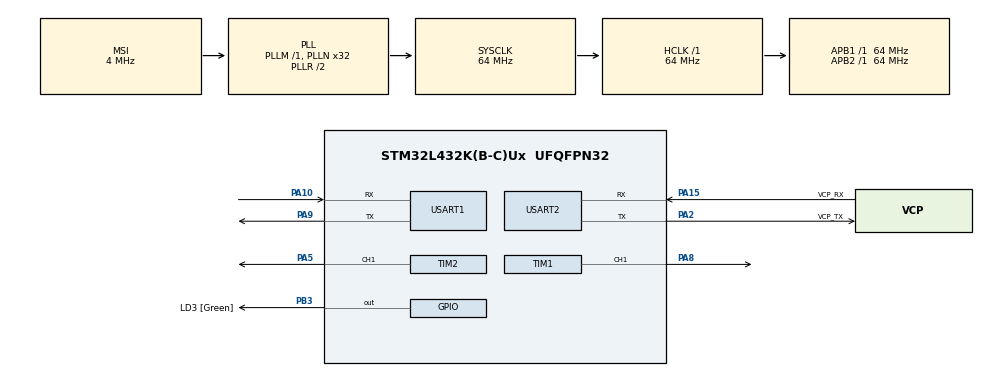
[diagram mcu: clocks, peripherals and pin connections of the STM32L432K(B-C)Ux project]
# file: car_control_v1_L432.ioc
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Mcu.Family=STM32L4
Mcu.Name=STM32L432K(B-C)Ux
Mcu.Package=UFQFPN32
NVIC.PriorityGroup=NVIC_PRIORITYGROUP_4
NVIC.USART1_IRQn=true\:0\:0\:false\:true\:true\:1\:true
NVIC.USART2_IRQn=true\:0\:0\:false\:true\:true\:2\:true
PA0.GPIO_Label=MCO [High speed clock in]
PA0.Mode=HSE-External-Clock-Source-for-LittleOrca
PA0.Signal=RCC_CK_IN
PA10.Mode=Asynchronous
PA10.Signal=USART1_RX
PA13\ (JTMS-SWDIO).GPIO_Label=SWDIO
PA13\ (JTMS-SWDIO).Mode=Serial_Wire
PA13\ (JTMS-SWDIO).Signal=SYS_JTMS-SWDIO
PA14\ (JTCK-SWCLK).GPIO_Label=SWCLK
PA14\ (JTCK-SWCLK).Mode=Serial_Wire
PA14\ (JTCK-SWCLK).Signal=SYS_JTCK-SWCLK
PA15\ (JTDI).GPIO_Label=VCP_RX
PA15\ (JTDI).Mode=Asynchronous
PA15\ (JTDI).Signal=USART2_RX
PA2.GPIO_Label=VCP_TX
PA2.Mode=Asynchronous
PA2.Signal=USART2_TX
PA5.Signal=S_TIM2_CH1
PA8.Signal=S_TIM1_CH1
PA9.Mode=Asynchronous
PA9.Signal=USART1_TX
PB3\ (JTDO-TRACESWO).GPIO_Label=LD3 [Green]
PB3\ (JTDO-TRACESWO).Signal=GPIO_Output
PC14-OSC32_IN\ (PC14).Mode=LSE-External-Oscillator
PC14-OSC32_IN\ (PC14).Signal=RCC_OSC32_IN
PC15-OSC32_OUT\ (PC15).Mode=LSE-External-Oscillator
PC15-OSC32_OUT\ (PC15).Signal=RCC_OSC32_OUT
ProjectManager.HeapSize=0x200
ProjectManager.StackSize=0x400
ProjectManager.TargetToolchain=TrueSTUDIO
RCC.ADCFreq_Value=16000000
RCC.AHBFreq_Value=64000000
RCC.APB1Freq_Value=64000000
RCC.APB1TimFreq_Value=64000000
RCC.APB2Freq_Value=64000000
RCC.APB2TimFreq_Value=64000000
RCC.CortexFreq_Value=64000000
RCC.HCLKFreq_Value=64000000
RCC.HSE_VALUE=8000000
RCC.HSI16_VALUE=16000000
RCC.HSI48_VALUE=48000000
RCC.HSI_VALUE=16000000
RCC.MSI_VALUE=4000000
RCC.PLLMUL=RCC_PLLMUL_4
RCC.PLLN=32
RCC.SYSCLKFreq_VALUE=64000000
RCC.SYSCLKSource=RCC_SYSCLKSOURCE_PLLCLK
RCC.USBFreq_Value=16000000
RCC.VCOOutputFreq_Value=128000000
SH.S_TIM1_CH1.0=TIM1_CH1,PWM Generation1 CH1
SH.S_TIM2_CH1.0=TIM2_CH1,PWM Generation1 CH1
TIM1.Channel-PWM\ Generation1\ CH1=TIM_CHANNEL_1
TIM1.Period=10000-1
TIM1.Prescaler=128-1
TIM1.Pulse-PWM\ Generation1\ CH1=760
TIM2.Channel-PWM\ Generation1\ CH1=TIM_CHANNEL_1
TIM2.Period=10000-1
TIM2.Prescaler=128-1
TIM2.Pulse-PWM\ Generation1\ CH1=760
USART1.VirtualMode-Asynchronous=VM_ASYNC
USART2.VirtualMode-Asynchronous=VM_ASYNC
board=NUCLEO-L432KC

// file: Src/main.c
/* USER CODE BEGIN Header */
/**
  ******************************************************************************
  * @file           : main.c
  * @brief          : Main program body
  ******************************************************************************
  ** This notice applies to any and all portions of this file
  * that are not between comment pairs USER CODE BEGIN and
  * USER CODE END. Other portions of this file, whether
  * inserted by the user or by software development tools
  * are owned by their respective copyright owners.
  *
  * COPYRIGHT(c) 2019 STMicroelectronics
  *
  * Redistribution and use in source and binary forms, with or without modification,
  * are permitted provided that the following conditions are met:
  *   1. Redistributions of source code must retain the above copyright notice,
  *      this list of conditions and the following disclaimer.
  *   2. Redistributions in binary form must reproduce the above copyright notice,
  *      this list of conditions and the following disclaimer in the documentation
  *      and/or other materials provided with the distribution.
  *   3. Neither the name of STMicroelectronics nor the names of its contributors
  *      may be used to endorse or promote products derived from this software
  *      without specific prior written permission.
  *
  * THIS SOFTWARE IS PROVIDED BY THE COPYRIGHT HOLDERS AND CONTRIBUTORS "AS IS"
  * AND ANY EXPRESS OR IMPLIED WARRANTIES, INCLUDING, BUT NOT LIMITED TO, THE
  * IMPLIED WARRANTIES OF MERCHANTABILITY AND FITNESS FOR A PARTICULAR PURPOSE ARE
  * DISCLAIMED. IN NO EVENT SHALL THE COPYRIGHT HOLDER OR CONTRIBUTORS BE LIABLE
  * FOR ANY DIRECT, INDIRECT, INCIDENTAL, SPECIAL, EXEMPLARY, OR CONSEQUENTIAL
  * DAMAGES (INCLUDING, BUT NOT LIMITED TO, PROCUREMENT OF SUBSTITUTE GOODS OR
  * SERVICES; LOSS OF USE, DATA, OR PROFITS; OR BUSINESS INTERRUPTION) HOWEVER
  * CAUSED AND ON ANY THEORY OF LIABILITY, WHETHER IN CONTRACT, STRICT LIABILITY,
  * OR TORT (INCLUDING NEGLIGENCE OR OTHERWISE) ARISING IN ANY WAY OUT OF THE USE
  * OF THIS SOFTWARE, EVEN IF ADVISED OF THE POSSIBILITY OF SUCH DAMAGE.
  *
  ******************************************************************************
  */
/* USER CODE END Header */

#include "main.h"

TIM_HandleTypeDef htim1;
TIM_HandleTypeDef htim2;

UART_HandleTypeDef huart1;
UART_HandleTypeDef huart2;

uint8_t rxBuffer[5]={0,};

uint8_t rcvFlag = 0;

uint8_t err_neg[40]="err!!Please Enter Positive Number\n\r";
uint8_t err_steer[40]="err!!Please Enter 0~31 Steer\n\r";
uint8_t err_speed[40]="err!!Please Enter 0~4 Speed\n\r";

int input;
int input_steer;
int input_speed;

int input_pwm1;
int input_pwm2;

void SystemClock_Config(void);
static void MX_GPIO_Init(void);
static void MX_USART2_UART_Init(void);
static void MX_USART1_UART_Init(void);
static void MX_TIM1_Init(void);
static void MX_TIM2_Init(void);
static void MX_NVIC_Init(void);
/* USER CODE BEGIN PFP */

static int ascii2int(uint8_t *value);

/* USER CODE END PFP */

int main(void)
{

  /* MCU Configuration--------------------------------------------------------*/

  /* Reset of all peripherals, Initializes the Flash interface and the Systick. */
  HAL_Init();

  /* Configure the system clock */
  SystemClock_Config();

  /* Initialize all configured peripherals */
  MX_GPIO_Init();
  MX_USART2_UART_Init();
  MX_USART1_UART_Init();
  MX_TIM1_Init();
  MX_TIM2_Init();

  /* Initialize interrupts */
  MX_NVIC_Init();
  /* USER CODE BEGIN 2 */
  HAL_TIM_PWM_Start(&htim1, TIM_CHANNEL_1);
  HAL_TIM_PWM_Start(&htim2, TIM_CHANNEL_1);
  /* USER CODE END 2 */

  /* Infinite loop */
  while (1)
  {
	  if(rcvFlag)
	  {
		  input = ascii2int(rxBuffer);
		  input_steer = input >> 3;
		  input_speed = input & 0x7;

		  if(input<0)
		  {
			  HAL_UART_Transmit(&huart2, err_neg, sizeof(err_neg), 10);
		  }
		  else if(input_steer>31)
		  {
			  HAL_UART_Transmit(&huart2, err_steer, sizeof(err_steer), 10);
		  }
		  else if(input_speed>4)
		  {
			  HAL_UART_Transmit(&huart2, err_speed, sizeof(err_speed), 10);
		  }
		  else
		  {
			  switch(input_steer>>4)
			  {
			  	  case 0:
			  	  {
			  		  input_pwm1 = 760-(220/15)*input_steer;
			  		  break;
			  	  }
			  	  case 1:
			  	  {
			  		  input_steer = input_steer & 0xf;
			  		  input_pwm1 = 760+(220/15)*input_steer;
			  		  break;
			  	  }
			  }
			  switch(input_speed)
			  {
			  	  case 0:
			  	  {
			  		  input_pwm2 = 760;
			  		  break;
			  	  }
			  	  case 1:
			  	  {
			  		  input_pwm2 = 820;
			  		  break;
			  	  }
			  	  case 2:
			  	  {
			  		  input_pwm2 = 825;
			  		  break;
			  	  }
			  	  case 3:
			  	  {
			  		  input_pwm2 = 830;
			  		  break;
			  	  }
			  	  case 4:
			  	  {
			  		  input_pwm2 = 690;
			  		  break;
			  	  }
			  }
		  }
		  TIM1->CCR1 = input_pwm1;
		  TIM2->CCR1 = input_pwm2;

		  rcvFlag = 0;
	  }

	  HAL_UART_Receive_IT(&huart2, rxBuffer, 3);

  }
	    /* USER CODE BEGIN 3 */
}

void SystemClock_Config(void)
{
  RCC_OscInitTypeDef RCC_OscInitStruct = {0};
  RCC_ClkInitTypeDef RCC_ClkInitStruct = {0};
  RCC_PeriphCLKInitTypeDef PeriphClkInit = {0};

  /**Configure LSE Drive Capability
  */
  HAL_PWR_EnableBkUpAccess();
  __HAL_RCC_LSEDRIVE_CONFIG(RCC_LSEDRIVE_LOW);
  /**Initializes the CPU, AHB and APB busses clocks
  */
  RCC_OscInitStruct.OscillatorType = RCC_OSCILLATORTYPE_LSE|RCC_OSCILLATORTYPE_MSI;
  RCC_OscInitStruct.LSEState = RCC_LSE_ON;
  RCC_OscInitStruct.MSIState = RCC_MSI_ON;
  RCC_OscInitStruct.MSICalibrationValue = 0;
  RCC_OscInitStruct.MSIClockRange = RCC_MSIRANGE_6;
  RCC_OscInitStruct.PLL.PLLState = RCC_PLL_ON;
  RCC_OscInitStruct.PLL.PLLSource = RCC_PLLSOURCE_MSI;
  RCC_OscInitStruct.PLL.PLLM = 1;
  RCC_OscInitStruct.PLL.PLLN = 32;
  RCC_OscInitStruct.PLL.PLLP = RCC_PLLP_DIV7;
  RCC_OscInitStruct.PLL.PLLQ = RCC_PLLQ_DIV2;
  RCC_OscInitStruct.PLL.PLLR = RCC_PLLR_DIV2;
  if (HAL_RCC_OscConfig(&RCC_OscInitStruct) != HAL_OK)
  {
    Error_Handler();
  }
  /**Initializes the CPU, AHB and APB busses clocks
  */
  RCC_ClkInitStruct.ClockType = RCC_CLOCKTYPE_HCLK|RCC_CLOCKTYPE_SYSCLK
                              |RCC_CLOCKTYPE_PCLK1|RCC_CLOCKTYPE_PCLK2;
  RCC_ClkInitStruct.SYSCLKSource = RCC_SYSCLKSOURCE_PLLCLK;
  RCC_ClkInitStruct.AHBCLKDivider = RCC_SYSCLK_DIV1;
  RCC_ClkInitStruct.APB1CLKDivider = RCC_HCLK_DIV1;
  RCC_ClkInitStruct.APB2CLKDivider = RCC_HCLK_DIV1;

  if (HAL_RCC_ClockConfig(&RCC_ClkInitStruct, FLASH_LATENCY_3) != HAL_OK)
  {
    Error_Handler();
  }
  PeriphClkInit.PeriphClockSelection = RCC_PERIPHCLK_USART1|RCC_PERIPHCLK_USART2;
  PeriphClkInit.Usart1ClockSelection = RCC_USART1CLKSOURCE_PCLK2;
  PeriphClkInit.Usart2ClockSelection = RCC_USART2CLKSOURCE_PCLK1;
  if (HAL_RCCEx_PeriphCLKConfig(&PeriphClkInit) != HAL_OK)
  {
    Error_Handler();
  }
  /**Configure the main internal regulator output voltage
  */
  if (HAL_PWREx_ControlVoltageScaling(PWR_REGULATOR_VOLTAGE_SCALE1) != HAL_OK)
  {
    Error_Handler();
  }
  /**Enable MSI Auto calibration
  */
  HAL_RCCEx_EnableMSIPLLMode();
}

/**
  * @brief NVIC Configuration.
  * @retval None
  */
static void MX_NVIC_Init(void)
{
  /* USART1_IRQn interrupt configuration */
  HAL_NVIC_SetPriority(USART1_IRQn, 0, 0);
  HAL_NVIC_EnableIRQ(USART1_IRQn);
  /* USART2_IRQn interrupt configuration */
  HAL_NVIC_SetPriority(USART2_IRQn, 0, 0);
  HAL_NVIC_EnableIRQ(USART2_IRQn);
}

void HAL_UART_RxCpltCallback(UART_HandleTypeDef *huart)
{
	rcvFlag=1;
	rxBuffer[3] = 10;
	rxBuffer[4] = 13;
	HAL_UART_Transmit(&huart2, rxBuffer, 5, 10);
}

static int ascii2int(uint8_t *value)
{
	int a;
	int b;
	int c;
	for(int i = 0; i < 2; i++)
	{
		a = (value[0]-48)*100;
		b = (value[1]-48)*10;
		c = value[2] - 48;
	}
	return a+b+c;
}

static void MX_TIM1_Init(void)
{

  TIM_MasterConfigTypeDef sMasterConfig = {0};
  TIM_OC_InitTypeDef sConfigOC = {0};
  TIM_BreakDeadTimeConfigTypeDef sBreakDeadTimeConfig = {0};

  htim1.Instance = TIM1;
  htim1.Init.Prescaler = 128-1;
  htim1.Init.CounterMode = TIM_COUNTERMODE_UP;
  htim1.Init.Period = 10000-1;
  htim1.Init.ClockDivision = TIM_CLOCKDIVISION_DIV1;
  htim1.Init.RepetitionCounter = 0;
  htim1.Init.AutoReloadPreload = TIM_AUTORELOAD_PRELOAD_DISABLE;
  if (HAL_TIM_PWM_Init(&htim1) != HAL_OK)
  {
    Error_Handler();
  }
  sMasterConfig.MasterOutputTrigger = TIM_TRGO_RESET;
  sMasterConfig.MasterOutputTrigger2 = TIM_TRGO2_RESET;
  sMasterConfig.MasterSlaveMode = TIM_MASTERSLAVEMODE_DISABLE;
  if (HAL_TIMEx_MasterConfigSynchronization(&htim1, &sMasterConfig) != HAL_OK)
  {
    Error_Handler();
  }
  sConfigOC.OCMode = TIM_OCMODE_PWM1;
  sConfigOC.Pulse = 760;
  sConfigOC.OCPolarity = TIM_OCPOLARITY_HIGH;
  sConfigOC.OCNPolarity = TIM_OCNPOLARITY_HIGH;
  sConfigOC.OCFastMode = TIM_OCFAST_DISABLE;
  sConfigOC.OCIdleState = TIM_OCIDLESTATE_RESET;
  sConfigOC.OCNIdleState = TIM_OCNIDLESTATE_RESET;
  if (HAL_TIM_PWM_ConfigChannel(&htim1, &sConfigOC, TIM_CHANNEL_1) != HAL_OK)
  {
    Error_Handler();
  }
  sBreakDeadTimeConfig.OffStateRunMode = TIM_OSSR_DISABLE;
  sBreakDeadTimeConfig.OffStateIDLEMode = TIM_OSSI_DISABLE;
  sBreakDeadTimeConfig.LockLevel = TIM_LOCKLEVEL_OFF;
  sBreakDeadTimeConfig.DeadTime = 0;
  sBreakDeadTimeConfig.BreakState = TIM_BREAK_DISABLE;
  sBreakDeadTimeConfig.BreakPolarity = TIM_BREAKPOLARITY_HIGH;
  sBreakDeadTimeConfig.BreakFilter = 0;
  sBreakDeadTimeConfig.Break2State = TIM_BREAK2_DISABLE;
  sBreakDeadTimeConfig.Break2Polarity = TIM_BREAK2POLARITY_HIGH;
  sBreakDeadTimeConfig.Break2Filter = 0;
  sBreakDeadTimeConfig.AutomaticOutput = TIM_AUTOMATICOUTPUT_DISABLE;
  if (HAL_TIMEx_ConfigBreakDeadTime(&htim1, &sBreakDeadTimeConfig) != HAL_OK)
  {
    Error_Handler();
  }
  HAL_TIM_MspPostInit(&htim1);

}

static void MX_TIM2_Init(void)
{

  TIM_MasterConfigTypeDef sMasterConfig = {0};
  TIM_OC_InitTypeDef sConfigOC = {0};

  htim2.Instance = TIM2;
  htim2.Init.Prescaler = 128-1;
  htim2.Init.CounterMode = TIM_COUNTERMODE_UP;
  htim2.Init.Period = 10000-1;
  htim2.Init.ClockDivision = TIM_CLOCKDIVISION_DIV1;
  htim2.Init.AutoReloadPreload = TIM_AUTORELOAD_PRELOAD_DISABLE;
  if (HAL_TIM_PWM_Init(&htim2) != HAL_OK)
  {
    Error_Handler();
  }
  sMasterConfig.MasterOutputTrigger = TIM_TRGO_RESET;
  sMasterConfig.MasterSlaveMode = TIM_MASTERSLAVEMODE_DISABLE;
  if (HAL_TIMEx_MasterConfigSynchronization(&htim2, &sMasterConfig) != HAL_OK)
  {
    Error_Handler();
  }
  sConfigOC.OCMode = TIM_OCMODE_PWM1;
  sConfigOC.Pulse = 760;
  sConfigOC.OCPolarity = TIM_OCPOLARITY_HIGH;
  sConfigOC.OCFastMode = TIM_OCFAST_DISABLE;
  if (HAL_TIM_PWM_ConfigChannel(&htim2, &sConfigOC, TIM_CHANNEL_1) != HAL_OK)
  {
    Error_Handler();
  }
  HAL_TIM_MspPostInit(&htim2);

}

static void MX_USART1_UART_Init(void)
{

  huart1.Instance = USART1;
  huart1.Init.BaudRate = 9600;
  huart1.Init.WordLength = UART_WORDLENGTH_8B;
  huart1.Init.StopBits = UART_STOPBITS_1;
  huart1.Init.Parity = UART_PARITY_NONE;
  huart1.Init.Mode = UART_MODE_TX_RX;
  huart1.Init.HwFlowCtl = UART_HWCONTROL_NONE;
  huart1.Init.OverSampling = UART_OVERSAMPLING_16;
  huart1.Init.OneBitSampling = UART_ONE_BIT_SAMPLE_DISABLE;
  huart1.AdvancedInit.AdvFeatureInit = UART_ADVFEATURE_NO_INIT;
  if (HAL_UART_Init(&huart1) != HAL_OK)
  {
    Error_Handler();
  }

}

static void MX_USART2_UART_Init(void)
{

  huart2.Instance = USART2;
  huart2.Init.BaudRate = 115200;
  huart2.Init.WordLength = UART_WORDLENGTH_8B;
  huart2.Init.StopBits = UART_STOPBITS_1;
  huart2.Init.Parity = UART_PARITY_NONE;
  huart2.Init.Mode = UART_MODE_TX_RX;
  huart2.Init.HwFlowCtl = UART_HWCONTROL_NONE;
  huart2.Init.OverSampling = UART_OVERSAMPLING_16;
  huart2.Init.OneBitSampling = UART_ONE_BIT_SAMPLE_DISABLE;
  huart2.AdvancedInit.AdvFeatureInit = UART_ADVFEATURE_NO_INIT;
  if (HAL_UART_Init(&huart2) != HAL_OK)
  {
    Error_Handler();
  }

}

static void MX_GPIO_Init(void)
{
  GPIO_InitTypeDef GPIO_InitStruct = {0};

  /* GPIO Ports Clock Enable */
  __HAL_RCC_GPIOC_CLK_ENABLE();
  __HAL_RCC_GPIOA_CLK_ENABLE();
  __HAL_RCC_GPIOB_CLK_ENABLE();

  /*Configure GPIO pin Output Level */
  HAL_GPIO_WritePin(LD3_GPIO_Port, LD3_Pin, GPIO_PIN_RESET);

  /*Configure GPIO pin : LD3_Pin */
  GPIO_InitStruct.Pin = LD3_Pin;
  GPIO_InitStruct.Mode = GPIO_MODE_OUTPUT_PP;
  GPIO_InitStruct.Pull = GPIO_NOPULL;
  GPIO_InitStruct.Speed = GPIO_SPEED_FREQ_LOW;
  HAL_GPIO_Init(LD3_GPIO_Port, &GPIO_InitStruct);

}

void Error_Handler(void)
{
}

/************************ (C) COPYRIGHT STMicroelectronics *****END OF FILE****/
